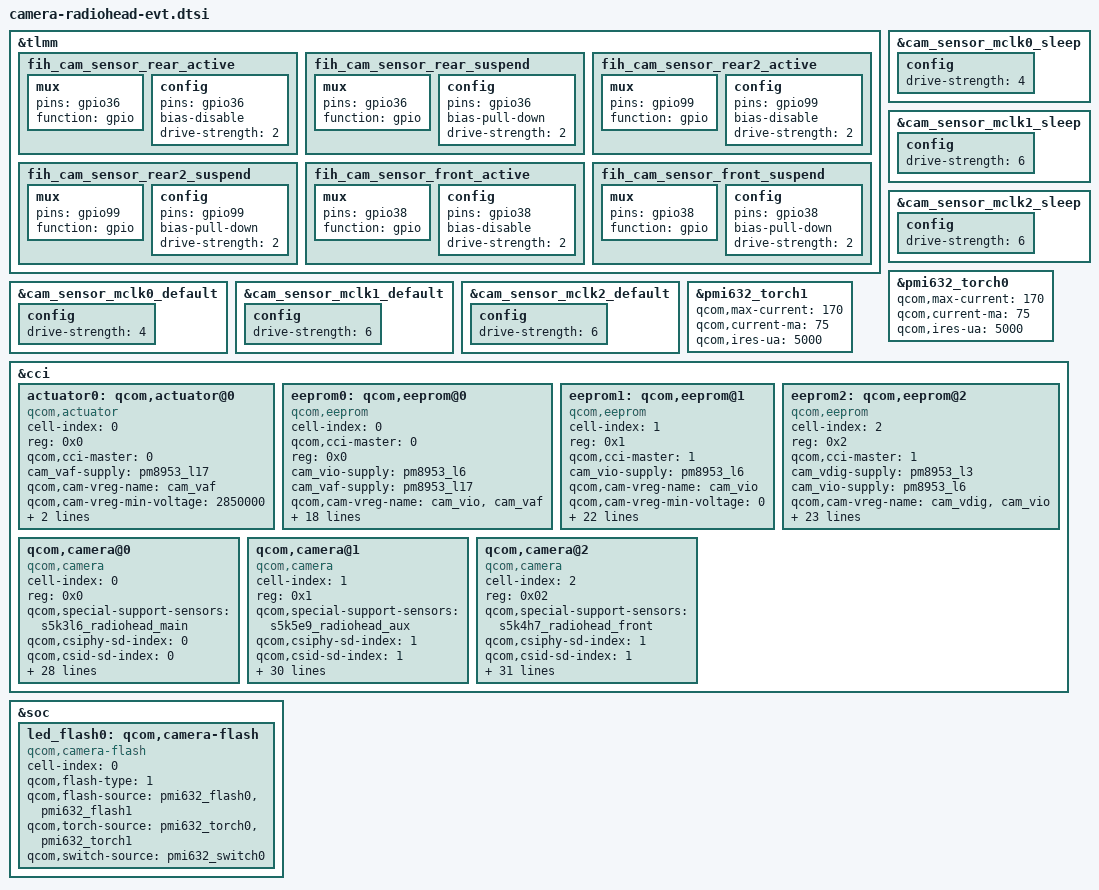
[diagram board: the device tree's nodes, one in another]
/*
 * Copyright (c) 2015-2016, 2018 The Linux Foundation. All rights reserved.
 *
 * This program is free software; you can redistribute it and/or modify
 * it under the terms of the GNU General Public License version 2 and
 * only version 2 as published by the Free Software Foundation.
 *
 * This program is distributed in the hope that it will be useful,
 * but WITHOUT ANY WARRANTY; without even the implied warranty of
 * MERCHANTABILITY or FITNESS FOR A PARTICULAR PURPOSE.  See the
 * GNU General Public License for more details.
 */

&tlmm {
		fih_cam_sensor_rear_active: fih_cam_sensor_rear_active {
			/* RESET */
			mux {
				pins = "gpio36";
				function = "gpio";
			};

			config {
				pins = "gpio36";
				bias-disable; /* No PULL */
				drive-strength = <2>; /* 2 MA */
			};
		};
		fih_cam_sensor_rear_suspend: fih_cam_sensor_rear_suspend {
			/* RESET */
			mux {
				pins = "gpio36";
				function = "gpio";
			};

			config {
				pins = "gpio36";
				bias-pull-down; /* PULL DOWN */
				drive-strength = <2>; /* 2 MA */
			};
		};

		fih_cam_sensor_rear2_active: fih_cam_sensor_rear2_active {
			/* RESET */
			mux {
				pins = "gpio99";
				function = "gpio";
			};

			config {
				pins = "gpio99";
				bias-disable; /* No PULL */
				drive-strength = <2>; /* 2 MA */
			};
		};
		fih_cam_sensor_rear2_suspend: fih_cam_sensor_rear2_suspend {
			/* RESET */
			mux {
				pins = "gpio99";
				function = "gpio";
			};

			config {
				pins = "gpio99";
				bias-pull-down; /* PULL DOWN */
				drive-strength = <2>; /* 2 MA */
			};
		};

		fih_cam_sensor_front_active: fih_cam_sensor_front_active {
			/* RESET */
			mux {
				pins = "gpio38";
				function = "gpio";
			};

			config {
				pins = "gpio38";
				bias-disable; /* No PULL */
				drive-strength = <2>; /* 2 MA */
			};
		};
		fih_cam_sensor_front_suspend: fih_cam_sensor_front_suspend {
			/* RESET */
			mux {
				pins = "gpio38";
				function = "gpio";
			};

			config {
				pins = "gpio38";
				bias-pull-down; /* PULL DOWN */
				drive-strength = <2>; /* 2 MA */
			};
		};
};

/*Camera De-sense, raise mclk driving strength from 2MA to 6mA*/
&cam_sensor_mclk0_default {
			config {
				drive-strength = <4>; /* 4 MA */
			};
};
&cam_sensor_mclk0_sleep {
			config {
				drive-strength = <4>; /* 4 MA */
			};
};
&cam_sensor_mclk1_default {
			config {
				drive-strength = <6>; /* 6 MA */
			};
};
&cam_sensor_mclk1_sleep {
			config {
				drive-strength = <6>; /* 6 MA */
			};
};
&cam_sensor_mclk2_default {
			config {
				drive-strength = <6>; /* 6 MA */
			};
};
&cam_sensor_mclk2_sleep {
			config {
				drive-strength = <6>; /* 6 MA */
			};
};

/*Modify Torch current*/
&pmi632_torch0 {
	qcom,max-current = <170>;
	qcom,current-ma = <75>;
	qcom,ires-ua = <5000>;
};

&pmi632_torch1 {
	qcom,max-current = <170>;
	qcom,current-ma = <75>;
	qcom,ires-ua = <5000>;
};

/* CCI portion*/
&cci {
		/delete-node/qcom,camera@0;
		/delete-node/qcom,camera@1;
		/delete-node/qcom,camera@2;
		/delete-node/qcom,camera@3;
		/delete-node/qcom,eeprom@0;
		/delete-node/qcom,eeprom@1;
		/delete-node/qcom,eeprom@2;
		/delete-node/qcom,actuator@0;
		/delete-node/qcom,actuator@1;
		/delete-node/qcom,actuator@2;
		/delete-node/qcom,ois@0;
};

&soc {
	led_flash0: qcom,camera-flash {
		cell-index = <0>;
		compatible = "qcom,camera-flash";
		qcom,flash-type = <1>;
		qcom,flash-source = <&pmi632_flash0 &pmi632_flash1>;
		qcom,torch-source = <&pmi632_torch0 &pmi632_torch1>;
		qcom,switch-source = <&pmi632_switch0>;
	};
};

&cci {
	actuator0: qcom,actuator@0 {
		cell-index = <0>;
		reg = <0x0>;
		compatible = "qcom,actuator";
		qcom,cci-master = <0>;
		cam_vaf-supply = <&pm8953_l17>;
		qcom,cam-vreg-name = "cam_vaf";
		qcom,cam-vreg-min-voltage = <2850000>;
		qcom,cam-vreg-max-voltage = <2850000>;
		qcom,cam-vreg-op-mode = <80000>;
	};
/*
	actuator1: qcom,actuator@1 {
		cell-index = <1>;
		reg = <0x1>;
		compatible = "qcom,actuator";
		qcom,cci-master = <0>;
		cam_vaf-supply = <&pm8953_l17>;
		qcom,cam-vreg-name = "cam_vaf";
		qcom,cam-vreg-min-voltage = <2850000>;
		qcom,cam-vreg-max-voltage = <2850000>;
		qcom,cam-vreg-op-mode = <80000>;
	};
*/
	eeprom0: qcom,eeprom@0 {
		cell-index = <0>;
		compatible = "qcom,eeprom";
		qcom,cci-master = <0>;
		reg = <0x0>;
		cam_vio-supply = <&pm8953_l6>;
		cam_vaf-supply = <&pm8953_l17>;
		qcom,cam-vreg-name = "cam_vio", "cam_vaf";
		qcom,cam-vreg-min-voltage = <0 2850000>;
		qcom,cam-vreg-max-voltage = <0 2850000>;
		qcom,cam-vreg-op-mode = <0 100000>;
		pinctrl-names = "cam_default", "cam_suspend";
		pinctrl-0 = <&cam_sensor_mclk0_default
				&fih_cam_sensor_rear_active>;
		pinctrl-1 = <&cam_sensor_mclk0_sleep
				&fih_cam_sensor_rear_suspend>;
		gpios = <&tlmm 26 0>,
			<&tlmm 36 0>,
			<&tlmm 92 0>,
			<&tlmm 39 0>;
		qcom,gpio-reset = <1>;
		qcom,gpio-vdig = <2>;
		qcom,gpio-vana = <3>;
		qcom,gpio-req-tbl-num = <0 1 2 3>;
		qcom,gpio-req-tbl-flags = <1 0 0 0>;
		qcom,gpio-req-tbl-label = "CAMIF_MCLK0",
			"CAM_RESET0",
			"CAM_VDIG",
			"CAM_VANA";
		status = "ok";
		clocks = <&clock_gcc clk_mclk0_clk_src>,
			<&clock_gcc clk_gcc_camss_mclk0_clk>;
		clock-names = "cam_src_clk", "cam_clk";
		qcom,clock-rates = <19200000 0>;
	};

	eeprom1: qcom,eeprom@1 {
		cell-index = <1>;
		reg = <0x1>;
		compatible = "qcom,eeprom";
		qcom,cci-master = <1>;
		cam_vio-supply = <&pm8953_l6>;
		qcom,cam-vreg-name = "cam_vio";
		qcom,cam-vreg-min-voltage = <0>;
		qcom,cam-vreg-max-voltage = <0>;
		qcom,cam-vreg-op-mode = <0>;
		pinctrl-names = "cam_default", "cam_suspend";
		pinctrl-0 = <&cam_sensor_mclk2_default
				&fih_cam_sensor_rear2_active>;
		pinctrl-1 = <&cam_sensor_mclk2_sleep
				&fih_cam_sensor_rear2_suspend>;
		gpios = <&tlmm 28 0>,
			<&tlmm 99 0>,
			<&tlmm 35 0>,
			<&tlmm 98 0>,
			<&tlmm 94 0>,
			<&tlmm 95 0>,
			<&tlmm 38 0>;
		qcom,gpio-reset = <1>;
		qcom,gpio-vdig = <2>;
		qcom,gpio-vana = <3>;
		qcom,gpio-custom1 = <4>;//CAM_SW_/OE
		qcom,gpio-custom2 = <5>;//CAM_SW_SEL
		qcom,gpio-custom3 = <6>;//FRONT_RESET
		qcom,gpio-req-tbl-num = <0 1 2 3 4 5 6>;
		qcom,gpio-req-tbl-flags = <1 0 0 0 0 0 0>;
		qcom,gpio-req-tbl-label = "CAMIF_MCLK2",
			"CAM_RESET1",
			"CAM_VDIG1",
			"CAM_VANA1",
			"CAM_CUSTOM1",
			"CAM_CUSTOM2",
            "CAM_RESET2";
		status = "ok";
		clocks = <&clock_gcc clk_mclk2_clk_src>,
			<&clock_gcc clk_gcc_camss_mclk2_clk>;
		clock-names = "cam_src_clk", "cam_clk";
		qcom,clock-rates = <19200000 0>;
	};

	eeprom2: qcom,eeprom@2 {
		cell-index = <2>;
		reg = <0x2>;
		compatible = "qcom,eeprom";
		qcom,cci-master = <1>;
		cam_vdig-supply = <&pm8953_l3>;
		cam_vio-supply = <&pm8953_l6>;
		qcom,cam-vreg-name = "cam_vdig", "cam_vio";
		qcom,cam-vreg-min-voltage = <1200000 0>;
		qcom,cam-vreg-max-voltage = <1200000 0>;
		qcom,cam-vreg-op-mode = <200000 0>;
		qcom,gpio-no-mux = <0>;
		pinctrl-names = "cam_default", "cam_suspend";
		pinctrl-0 = <&cam_sensor_mclk1_default
				&fih_cam_sensor_front_active>;
		pinctrl-1 = <&cam_sensor_mclk1_sleep
				&fih_cam_sensor_front_suspend>;
		gpios = <&tlmm 27 0>,
		  <&tlmm 46 0>,
			<&tlmm 38 0>,
			<&tlmm 94 0>,
			<&tlmm 95 0>,
			<&tlmm 99 0>;
		qcom,gpio-vana = <1>;
		qcom,gpio-reset = <2>;
		qcom,gpio-custom1 = <3>;//CAM_SW_/OE
		qcom,gpio-custom2 = <4>;//CAM_SW_SEL
		qcom,gpio-custom3 = <5>;//AUX_RESET
		qcom,gpio-req-tbl-num = <0 1 2 3 4 5>;
		qcom,gpio-req-tbl-flags = <1 0 0 0 0 0>;
		qcom,gpio-req-tbl-label = "CAMIF_MCLK1",
					  "CAM_VANA2",
					  "CAM_RESET2",
					  "CAM_CUSTOM1",
			      "CAM_CUSTOM2",
                  "CAM_RESET1";
		status = "ok";
		clocks = <&clock_gcc clk_mclk1_clk_src>,
			<&clock_gcc clk_gcc_camss_mclk1_clk>;
		clock-names = "cam_src_clk", "cam_clk";
		qcom,clock-rates = <19200000 0>;
	};

	qcom,camera@0 {
		cell-index = <0>;
		compatible = "qcom,camera";
		reg = <0x0>;
        qcom,special-support-sensors = "s5k3l6_radiohead_main";
		qcom,csiphy-sd-index = <0>;
		qcom,csid-sd-index = <0>;
		qcom,mount-angle = <90>;
		qcom,led-flash-src = <&led_flash0>;
		qcom,eeprom-src = <&eeprom0>;
		qcom,actuator-src = <&actuator0>;
		cam_vio-supply = <&pm8953_l6>;
		cam_vaf-supply = <&pm8953_l17>;
		qcom,cam-vreg-name = "cam_vio", "cam_vaf";
		qcom,cam-vreg-min-voltage = <0 2850000>;
		qcom,cam-vreg-max-voltage = <0 2850000>;
		qcom,cam-vreg-op-mode = <0 100000>;
		pinctrl-names = "cam_default", "cam_suspend";
		pinctrl-0 = <&cam_sensor_mclk0_default
				&fih_cam_sensor_rear_active>;
		pinctrl-1 = <&cam_sensor_mclk0_sleep
				&fih_cam_sensor_rear_suspend>;
		gpios = <&tlmm 26 0>,
			<&tlmm 36 0>,
			<&tlmm 92 0>,
			<&tlmm 39 0>;
		qcom,gpio-reset = <1>;
		qcom,gpio-vdig = <2>;
		qcom,gpio-vana = <3>;
		qcom,gpio-req-tbl-num = <0 1 2 3>;
		qcom,gpio-req-tbl-flags = <1 0 0 0>;
		qcom,gpio-req-tbl-label = "CAMIF_MCLK0",
			"CAM_RESET0",
			"CAM_VDIG",
			"CAM_VANA";
		qcom,sensor-position = <0>;
		qcom,sensor-mode = <0>;
		qcom,cci-master = <0>;
		status = "ok";
		clocks = <&clock_gcc clk_mclk0_clk_src>,
				<&clock_gcc clk_gcc_camss_mclk0_clk>;
		clock-names = "cam_src_clk", "cam_clk";
		qcom,clock-rates = <24000000 0>;
	};

	qcom,camera@1 {
		cell-index = <1>;
		compatible = "qcom,camera";
		reg = <0x1>;
        qcom,special-support-sensors = "s5k5e9_radiohead_aux";
		qcom,csiphy-sd-index = <1>;
		qcom,csid-sd-index = <1>;
		qcom,mount-angle = <90>;
		qcom,eeprom-src = <&eeprom1>;
		cam_vio-supply = <&pm8953_l6>;
		qcom,cam-vreg-name = "cam_vio";
		qcom,cam-vreg-min-voltage = <0>;
		qcom,cam-vreg-max-voltage = <0>;
		qcom,cam-vreg-op-mode = <0>;
		pinctrl-names = "cam_default", "cam_suspend";
		pinctrl-0 = <&cam_sensor_mclk2_default
				&fih_cam_sensor_rear2_active>;
		pinctrl-1 = <&cam_sensor_mclk2_sleep
				&fih_cam_sensor_rear2_suspend>;
		gpios = <&tlmm 28 0>,
			<&tlmm 99 0>,
			<&tlmm 35 0>,
			<&tlmm 98 0>,
			<&tlmm 94 0>,
			<&tlmm 95 0>,
			<&tlmm 38 0>;
		qcom,gpio-reset = <1>;
		qcom,gpio-vdig = <2>;
		qcom,gpio-vana = <3>;
		qcom,gpio-custom1 = <4>;//CAM_SW_/OE
		qcom,gpio-custom2 = <5>;//CAM_SW_SEL
		qcom,gpio-custom3 = <6>;//FRONT_RESET
		qcom,gpio-req-tbl-num = <0 1 2 3 4 5 6>;
		qcom,gpio-req-tbl-flags = <1 0 0 0 0 0 0>;
		qcom,gpio-req-tbl-label = "CAMIF_MCLK2",
			"CAM_RESET1",
			"CAM_VDIG1",
			"CAM_VANA1",
			"CAM_CUSTOM1",
			"CAM_CUSTOM2",
            "CAM_RESET2";
		qcom,sensor-position = <0>;
		qcom,sensor-mode = <0>;
		qcom,cci-master = <1>;
		status = "ok";
		clocks = <&clock_gcc clk_mclk2_clk_src>,
				<&clock_gcc clk_gcc_camss_mclk2_clk>;
		clock-names = "cam_src_clk", "cam_clk";
		qcom,clock-rates = <24000000 0>;
	};

	qcom,camera@2 {
		cell-index = <2>;
		compatible = "qcom,camera";
		reg = <0x02>;
		qcom,special-support-sensors = "s5k4h7_radiohead_front";
		qcom,csiphy-sd-index = <1>;
		qcom,csid-sd-index = <1>;
		qcom,mount-angle = <270>;
		qcom,eeprom-src = <&eeprom2>;
		//qcom,actuator-src = <&actuator1>;
		cam_vdig-supply = <&pm8953_l3>;
		cam_vio-supply = <&pm8953_l6>;
		qcom,cam-vreg-name = "cam_vdig", "cam_vio";
		qcom,cam-vreg-min-voltage = <1200000 0>;
		qcom,cam-vreg-max-voltage = <1200000 0>;
		qcom,cam-vreg-op-mode = <200000 0>;
		qcom,gpio-no-mux = <0>;
		pinctrl-names = "cam_default", "cam_suspend";
		pinctrl-0 = <&cam_sensor_mclk1_default
				&fih_cam_sensor_front_active>;
		pinctrl-1 = <&cam_sensor_mclk1_sleep
				&fih_cam_sensor_front_suspend>;
		gpios = <&tlmm 27 0>,
		  <&tlmm 46 0>,
			<&tlmm 38 0>,
			<&tlmm 94 0>,
			<&tlmm 95 0>,
			<&tlmm 99 0>;
		qcom,gpio-vana = <1>;
		qcom,gpio-reset = <2>;
		qcom,gpio-custom1 = <3>;//CAM_SW_/OE
		qcom,gpio-custom2 = <4>;//CAM_SW_SEL
		qcom,gpio-custom3 = <5>;//AUX_RESET
		qcom,gpio-req-tbl-num = <0 1 2 3 4 5>;
		qcom,gpio-req-tbl-flags = <1 0 0 0 0 0>;
		qcom,gpio-req-tbl-label = "CAMIF_MCLK1",
					  "CAM_VANA2",
					  "CAM_RESET2",
					  "CAM_CUSTOM1",
			      "CAM_CUSTOM2",
                  "CAM_RESET1";
		qcom,sensor-position = <1>;
		qcom,sensor-mode = <0>;
		qcom,cci-master = <1>;
		status = "ok";
		clocks = <&clock_gcc clk_mclk1_clk_src>,
			<&clock_gcc clk_gcc_camss_mclk1_clk>;
		clock-names = "cam_src_clk", "cam_clk";
		qcom,clock-rates = <24000000 0>;
	};
};
